# bcm2837_lpa register map
Vendor: BROADCOM; Series: BCM2837; File version: A
CPU: CA72 r0p0, little endian, MPU, FPU, 2 interrupt priority bits
Registers are 32-bit, read-write, reset 0x0 unless marked. A register's access mark holds for its fields unless they carry their own. Offsets are from the block's base; [hi:lo] are bit positions; {n}, {i} and the like mark numbered series; 'fields as' and 'values as' point back to an identical list.

## EMMC — Arasan SD3.0 Host AHB eMMC 4.4
Base 0x3F300000
0x00 ARG2 — Argument for ACMD23 command
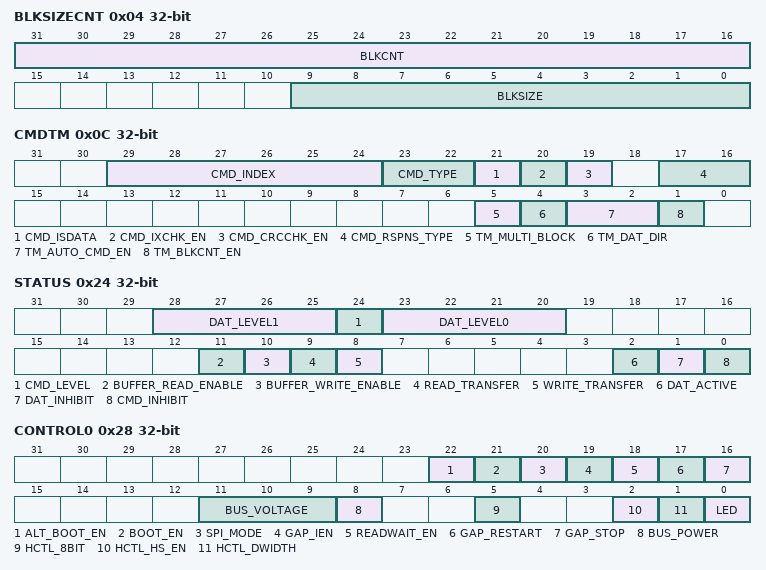
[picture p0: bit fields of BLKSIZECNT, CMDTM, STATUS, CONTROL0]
0x04 BLKSIZECNT — Numer and size in bytes for data block to be transferred
  [31:16] BLKCNT — Number of blocks to be transferred
  [9:0] BLKSIZE — Block size in bytes
0x08 ARG1 — Argument for everything but ACMD23
0x0C CMDTM — Issue commands to the card
  [29:24] CMD_INDEX — Command index to be issued
  [23:22] CMD_TYPE — Type of command to be issued
    0=NORMAL; 1=SUSPEND; 2=RESUME; 3=ABORT
  [21] CMD_ISDATA — Command involves data
  [20] CMD_IXCHK_EN — Check that the response has the same command index
  [19] CMD_CRCCHK_EN — Check the responses CRC
  [17:16] CMD_RSPNS_TYPE — Type of expected response
    0=NONE; 1=136BITS; 2=48BITS; 3=48BITS_USING_BUSY
  [5] TM_MULTI_BLOCK — Type of data transfer
    0=SINGLE; 1=MULTIPLE
  [4] TM_DAT_DIR — Direction of data transfer
    0=HOST_TO_CARD; 1=CARD_TO_HOST
  [3:2] TM_AUTO_CMD_EN — Command after completion
    0=NONE; 1=CMD12; 2=CMD23
  [1] TM_BLKCNT_EN — Enable block counter
0x10 RESP0 — Status bits of the response
{0x10+4i} RESP{i} (i=1..3) — Bits {32i+31}:{32i} of CMD2 and CMD10 responses
0x20 DATA — Data to/from the card
0x24 STATUS — Status info for debugging
  [28:25] DAT_LEVEL1 — Value of DAT[7:4]
  [24] CMD_LEVEL — Value of CMD
  [23:20] DAT_LEVEL0 — Value of DAT[3:0]
  [11] BUFFER_READ_ENABLE — New data is available to read
  [10] BUFFER_WRITE_ENABLE — The buffer has space for new data
  [9] READ_TRANSFER — Read transfer is active
  [8] WRITE_TRANSFER — Write transfer is active
  [2] DAT_ACTIVE — At least one data line is active
  [1] DAT_INHIBIT — Data lines still in use
  [0] CMD_INHIBIT — Command line still in use
0x28 CONTROL0 — Control
  [22] ALT_BOOT_EN — Enable alternate boot mode
  [21] BOOT_EN — Boot mode enabled
  [20] SPI_MODE — Enable SPI mode
  [19] GAP_IEN — Enable interrupt on block gap
  [18] READWAIT_EN — Use DAT2 read/wait protocol
  [17] GAP_RESTART — Restart a transaction stopped by GAP_STOP
  [16] GAP_STOP — Stop the current transaction at the next block gap
  [11:9] BUS_VOLTAGE
    5=V1_8; 6=V3_0; 7=V3_3
  [8] BUS_POWER
  [5] HCTL_8BIT — Use 8 data lines
  [2] HCTL_HS_EN — Enable high speed mode
  [1] HCTL_DWIDTH — Use 4 data lines
  [0] LED
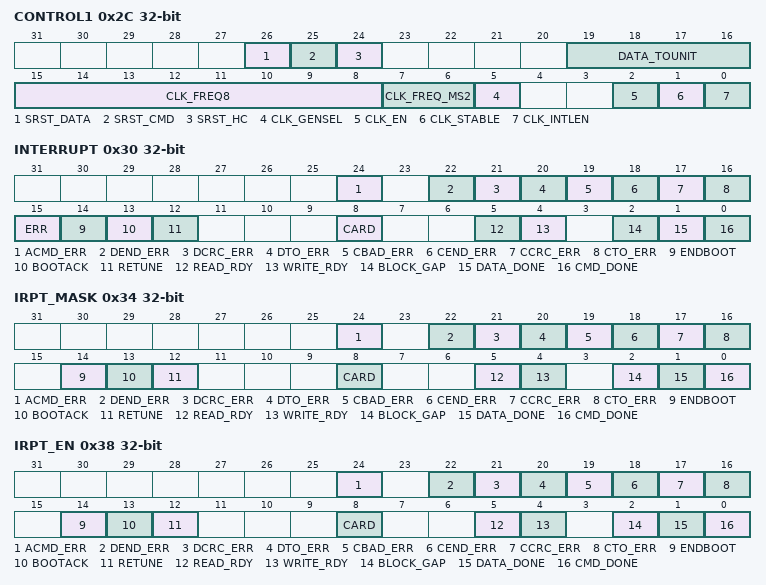
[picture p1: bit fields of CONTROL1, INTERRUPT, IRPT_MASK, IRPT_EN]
0x2C CONTROL1 — Configure
  [26] SRST_DATA — Reset the data handling circuit
  [25] SRST_CMD — Reset the command handling circuit
  [24] SRST_HC — Reset the complete host circuit
  [19:16] DATA_TOUNIT — Data timeout exponent (TMCLK * 2 ** (x + 13)) 1111 disabled
  [15:8] CLK_FREQ8 — Clock base divider LSB
  [7:6] CLK_FREQ_MS2 — Clock base divider MSBs
  [5] CLK_GENSEL — Mode of clock generation
    0=DIVIDED; 1=PROGRAMMABLE
  [2] CLK_EN — SD Clock enable
  [1] CLK_STABLE ro — SD Clock stable
  [0] CLK_INTLEN — Enable internal clock
0x30 INTERRUPT — Interrupt flags
  [24] ACMD_ERR — Auto command error
  [22] DEND_ERR — Data end bit error (not 1)
  [21] DCRC_ERR — Data CRC error
  [20] DTO_ERR — Data timeout
  [19] CBAD_ERR — Incorrect response command index
  [18] CEND_ERR — Command end bit error (not 1)
  [17] CCRC_ERR — Command CRC error
  [16] CTO_ERR — Command timeout
  [15] ERR ro — An error has occured
  [14] ENDBOOT — Boot operation has terminated
  [13] BOOTACK — Boot has been acknowledged
  [12] RETUNE — Clock retune request
  [8] CARD — Card made interrupt request
  [5] READ_RDY — DATA contains data to be read
  [4] WRITE_RDY — DATA can be written to
  [2] BLOCK_GAP — Data transfer has stopped at block gap
  [1] DATA_DONE — Data transfer has finished
  [0] CMD_DONE — Command has finished
0x34 IRPT_MASK — Mask interrupts that change in INTERRUPT
  [24] ACMD_ERR — Auto command error
  [22] DEND_ERR — Data end bit error (not 1)
  [21] DCRC_ERR — Data CRC error
  [20] DTO_ERR — Data timeout
  [19] CBAD_ERR — Incorrect response command index
  [18] CEND_ERR — Command end bit error (not 1)
  [17] CCRC_ERR — Command CRC error
  [16] CTO_ERR — Command timeout
  [14] ENDBOOT — Boot operation has terminated
  [13] BOOTACK — Boot has been acknowledged
  [12] RETUNE — Clock retune request
  [8] CARD — Card made interrupt request
  [5] READ_RDY — DATA contains data to be read
  [4] WRITE_RDY — DATA can be written to
  [2] BLOCK_GAP — Data transfer has stopped at block gap
  [1] DATA_DONE — Data transfer has finished
  [0] CMD_DONE — Command has finished
0x38 IRPT_EN — Enable interrupt to core
  fields as IRPT_MASK
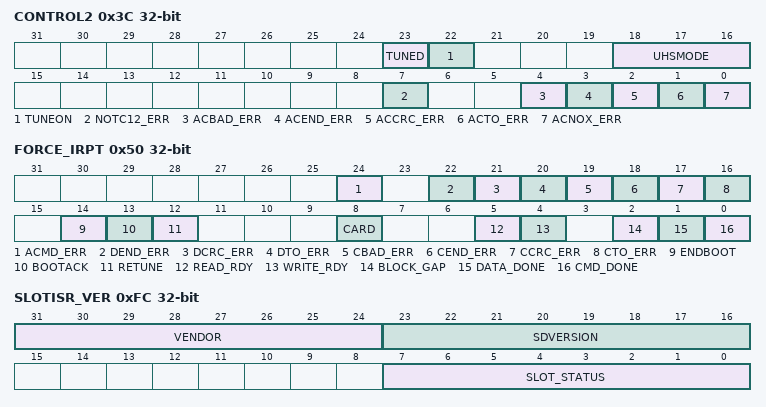
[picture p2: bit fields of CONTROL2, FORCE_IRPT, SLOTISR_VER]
0x3C CONTROL2
  [23] TUNED — Tuned clock is used for sampling data
  [22] TUNEON — SD Clock tune in progress
  [18:16] UHSMODE — Select the speed of the SD card
    0=SDR12; 1=SDR25; 2=SDR50; 3=SDR104; 4=DDR50
  [7] NOTC12_ERR ro — Error during auto CMD12
  [4] ACBAD_ERR ro — Command index error during auto command
  [3] ACEND_ERR ro — End bit is not 1 during auto command
  [2] ACCRC_ERR ro — Command CRC error during auto command
  [1] ACTO_ERR ro — Auto command timeout
  [0] ACNOX_ERR ro — Auto command not executed due to an error
0x50 FORCE_IRPT — Force an interrupt
  fields as IRPT_MASK
0x70 BOOT_TIMEOUT — Number of SD clock cycles to wait for boot
0x74 DBG_SEL — What submodules are accessed by the debug bus
  [0] SELECT
    0=RECEIVER_FIFO; 1=OTHERS
0x80 EXRDFIFO_CFG — Fine tune DMA request generation
  [2:0] RD_THRSH — Read threshold in 32 bit words
0x84 EXRDFIFO_EN — Enable the extension data register
  [0] ENABLE — Enable the extension FIFO
0x88 TUNE_STEP — Sample clock delay step duration
  [2:0] DELAY
0x8C TUNE_STEPS_STD — Sample clock delay step count for SDR
  [5:0] STEPS
0x90 TUNE_STEPS_DDR — Sample clock delay step count for DDR
  [5:0] STEPS
0xF0 SPI_INT_SPT — Interrupts in SPI mode depend on CS
  [7:0] SELECT
0xFC SLOTISR_VER — Version information and slot interrupt status
  [31:24] VENDOR — Vendor version number
  [23:16] SDVERSION — Host controller specification version
  [7:0] SLOT_STATUS — OR of interrupt and wakeup signals for each slot
